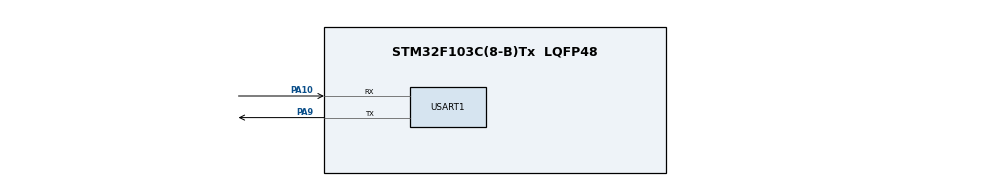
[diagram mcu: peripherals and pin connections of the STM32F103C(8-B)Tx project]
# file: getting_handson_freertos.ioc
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Mcu.Family=STM32F1
Mcu.Name=STM32F103C(8-B)Tx
Mcu.Package=LQFP48
NVIC.PriorityGroup=NVIC_PRIORITYGROUP_4
NVIC.TIM1_UP_IRQn=true\:15\:0\:false\:false\:true\:false\:true\:true
NVIC.TimeBase=TIM1_UP_IRQn
NVIC.TimeBaseIP=TIM1
NVIC.USART1_IRQn=true\:6\:0\:true\:false\:true\:true\:true\:true
PA10.Mode=Asynchronous
PA10.Signal=USART1_RX
PA9.Mode=Asynchronous
PA9.Signal=USART1_TX
ProjectManager.HeapSize=0x200
ProjectManager.StackSize=0x400
ProjectManager.TargetToolchain=STM32CubeIDE
RCC.APB1Freq_Value=8000000
RCC.APB2Freq_Value=8000000
USART1.VirtualMode=VM_ASYNC
VP_RTC_VS_RTC_Activate.Mode=RTC_Enabled
VP_SYS_VS_tim1.Mode=TIM1
board=custom

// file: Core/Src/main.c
/* USER CODE BEGIN Header */
/**
  ******************************************************************************
  * @file           : main.c
  * @brief          : Main program body
  ******************************************************************************
  * @attention
  *
  * Copyright (c) 2026 STMicroelectronics.
  * All rights reserved.
  *
  * This software is licensed under terms that can be found in the LICENSE file
  * in the root directory of this software component.
  * If no LICENSE file comes with this software, it is provided AS-IS.
  *
  ******************************************************************************
  */
/* USER CODE END Header */
#include "main.h"

/* USER CODE BEGIN Includes */
#include "FreeRTOS.h"
#include "task.h"
#include "queue.h"

/* USER CODE END Includes */

RTC_HandleTypeDef hrtc;

UART_HandleTypeDef huart1;

TaskHandle_t menu_task_h = NULL;
TaskHandle_t cmd_task_h = NULL;
TaskHandle_t print_task_h = NULL;
TaskHandle_t led_task_h = NULL;
TaskHandle_t rtc_task_h = NULL;

xQueueHandle q_data, q_print;
UBaseType_t Task_Returned;

volatile uint8_t user_data;

/* USER CODE BEGIN PV */
int __io_putchar(int ch){

	  HAL_UART_Transmit(&huart1, (uint8_t*)&ch, 1 , HAL_MAX_DELAY);
	  return ch;
};

void HAL_UART_RxCpltCallback(UART_HandleTypeDef *huart)
{

	 void * const pvBuffe;

	// check: if queue is not full
	/* xQueueIsQueueFullFromISR :: Queries a queue to determine if the queue is full.
	 * This function should only be used in an ISR.*/
	if(xQueueIsQueueFullFromISR(q_data) =! pdTRUE )
	{
			/*Queue is not full , Enqueue data byte */

		xQueueSendFromISR(q_data, &user_data , pdFALSE);

	}else
	{
			/*Queue is full */

		if(user_data == '\n')
		{
			/* make sure that last data byte of the queue is '\n' */
			xQueueReceiveFromISR(q_data, pvBuffer , pdFALSE );
			xQueueSendFromISR(q_data, user_data , pdFALSE );

		}
	}

		/*send notification to command handling task if user_data = '\n' */
	if(user_data == '\n')
	{
		xTaskNotifyFromISR( cmd_task_h,0 ,eNoAction,pfFALSE );
	}

		/* TODO: Enable UART data byte reception again in IT mode */
	  HAL_UART_Receive_IT(&huart1, &user_data, 1);

}

/* USER CODE END PV */

void SystemClock_Config(void);
static void MX_GPIO_Init(void);
static void MX_USART1_UART_Init(void);
static void MX_RTC_Init(void);

int main(void)
{

  /* MCU Configuration--------------------------------------------------------*/

  /* Reset of all peripherals, Initializes the Flash interface and the Systick. */
  HAL_Init();

  /* Configure the system clock */
  SystemClock_Config();

  /* Initialize all configured peripherals */
  MX_GPIO_Init();
  MX_USART1_UART_Init();
  MX_RTC_Init();
  /* USER CODE BEGIN 2 */

  Task_Returned = xTaskCreate(
    		  menu_task,
    		  "T1",
    		  250 ,
    		  (void*)1,
    		  1,
    		  &menu_task_h);
  configASSERT(Task_Returned == pdPASS);

  Task_Returned = xTaskCreate(
     		  cmd_task,
     		  "T2",
     		  250 ,
     		  (void*)1,
     		  1,
     		  &cmd_task_h);
  configASSERT(Task_Returned == pdPASS);

  Task_Returned = xTaskCreate(
         		  print_task,
         		  "T3",
         		  250 ,
         		  (void*)1,
         		  1,
         		  &print_task_h);
  configASSERT(Task_Returned == pdPASS);

  Task_Returned = xTaskCreate(
         		  led_task,
         		  "T4",
         		  250 ,
         		  (void*)1,
         		  1,
         		  &led_task_h);
  configASSERT(Task_Returned == pdPASS);

  Task_Returned = xTaskCreate(
         		  rtc_task,
         		  "T5",
         		  250 ,
         		  (void*)1,
         		  1,
         		  &rtc_task_h);
  configASSERT(Task_Returned == pdPASS);

  q_data = xQueueCreate(10, sizeof(char));
  configASSERT(q_data != NULL);

  q_print = xQueueCreate(10, sizeof(size_t)); // pointer size
  configASSERT(q_print != NULL);

  /**Enabling Data Receiving via uart in IT mode ***/
  HAL_UART_Receive_IT(&huart1, &user_data, 1);

  vTaskStartScheduler();

  /* USER CODE END 2 */

  /* Infinite loop */
  while (1)
  {

  }
}

void SystemClock_Config(void)
{
  RCC_OscInitTypeDef RCC_OscInitStruct = {0};
  RCC_ClkInitTypeDef RCC_ClkInitStruct = {0};
  RCC_PeriphCLKInitTypeDef PeriphClkInit = {0};

  /** Initializes the RCC Oscillators according to the specified parameters
  * in the RCC_OscInitTypeDef structure.
  */
  RCC_OscInitStruct.OscillatorType = RCC_OSCILLATORTYPE_HSI|RCC_OSCILLATORTYPE_LSI;
  RCC_OscInitStruct.HSIState = RCC_HSI_ON;
  RCC_OscInitStruct.HSICalibrationValue = RCC_HSICALIBRATION_DEFAULT;
  RCC_OscInitStruct.LSIState = RCC_LSI_ON;
  RCC_OscInitStruct.PLL.PLLState = RCC_PLL_NONE;
  if (HAL_RCC_OscConfig(&RCC_OscInitStruct) != HAL_OK)
  {
    Error_Handler();
  }

  /** Initializes the CPU, AHB and APB buses clocks
  */
  RCC_ClkInitStruct.ClockType = RCC_CLOCKTYPE_HCLK|RCC_CLOCKTYPE_SYSCLK
                              |RCC_CLOCKTYPE_PCLK1|RCC_CLOCKTYPE_PCLK2;
  RCC_ClkInitStruct.SYSCLKSource = RCC_SYSCLKSOURCE_HSI;
  RCC_ClkInitStruct.AHBCLKDivider = RCC_SYSCLK_DIV1;
  RCC_ClkInitStruct.APB1CLKDivider = RCC_HCLK_DIV1;
  RCC_ClkInitStruct.APB2CLKDivider = RCC_HCLK_DIV1;

  if (HAL_RCC_ClockConfig(&RCC_ClkInitStruct, FLASH_LATENCY_0) != HAL_OK)
  {
    Error_Handler();
  }
  PeriphClkInit.PeriphClockSelection = RCC_PERIPHCLK_RTC;
  PeriphClkInit.RTCClockSelection = RCC_RTCCLKSOURCE_LSI;
  if (HAL_RCCEx_PeriphCLKConfig(&PeriphClkInit) != HAL_OK)
  {
    Error_Handler();
  }
}

static void MX_RTC_Init(void)
{

  /** Initialize RTC Only
  */
  hrtc.Instance = RTC;
  hrtc.Init.AsynchPrediv = RTC_AUTO_1_SECOND;
  hrtc.Init.OutPut = RTC_OUTPUTSOURCE_ALARM;
  if (HAL_RTC_Init(&hrtc) != HAL_OK)
  {
    Error_Handler();
  }

}

static void MX_USART1_UART_Init(void)
{

  huart1.Instance = USART1;
  huart1.Init.BaudRate = 115200;
  huart1.Init.WordLength = UART_WORDLENGTH_8B;
  huart1.Init.StopBits = UART_STOPBITS_1;
  huart1.Init.Parity = UART_PARITY_NONE;
  huart1.Init.Mode = UART_MODE_TX_RX;
  huart1.Init.HwFlowCtl = UART_HWCONTROL_NONE;
  huart1.Init.OverSampling = UART_OVERSAMPLING_16;
  if (HAL_UART_Init(&huart1) != HAL_OK)
  {
    Error_Handler();
  }

}

static void MX_GPIO_Init(void)
{

  /* GPIO Ports Clock Enable */
  __HAL_RCC_GPIOA_CLK_ENABLE();

}

void HAL_TIM_PeriodElapsedCallback(TIM_HandleTypeDef *htim)
{
  if (htim->Instance == TIM1) {
    HAL_IncTick();
  }
}

void Error_Handler(void)
{
  __disable_irq();
  while (1)
  {
  }
}
